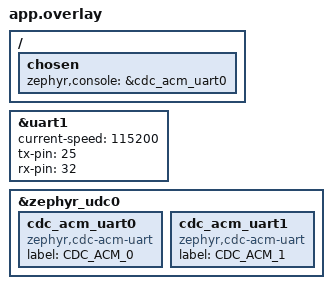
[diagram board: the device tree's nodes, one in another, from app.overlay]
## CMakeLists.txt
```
#
# Copyright (c) Ericsson AB 2020, all rights reserved
#

cmake_minimum_required(VERSION 3.8.2)

set(APP_VERSION "0.10")

# Include Ardesco SDK 
set(AR $ENV{ARDESCO_ROOT})
if(DEFINED AR)
   include($ENV{ARDESCO_ROOT}/ardesco.cmake)
else()
   # Assume we are building from the apps folder in Ardesco tree
   include(${CMAKE_CURRENT_SOURCE_DIR}/../../ardesco.cmake)
endif()

project(IPC52_Simple)

target_sources(app PRIVATE src/main.c)

# Add lib for 91-52 communication 
add_subdirectory(${ARDESCO_LIB_DIR}/ipclib ${CMAKE_BINARY_DIR}/lib/ipclib)

# Add lib for serial on 52840
add_subdirectory(${ARDESCO_LIB_DIR}/serial_52lib ${CMAKE_BINARY_DIR}/lib/serial_52lib)

# Add lib for usb support on 52840
add_subdirectory(${ARDESCO_LIB_DIR}/usb_uart_52lib ${CMAKE_BINARY_DIR}/lib/usb_uart_52lib)
```

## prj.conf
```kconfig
#
# Copyright (c) Ericsson AB 2020, all rights reserved
#

#General
CONFIG_REBOOT=y
CONFIG_HEAP_MEM_POOL_SIZE=16384
CONFIG_GPIO=y
CONFIG_POLL=y
CONFIG_BOOTLOADER_MCUBOOT=y

 # USB
CONFIG_USB_DEVICE_STACK=y
CONFIG_USB_DEVICE_MANUFACTURER="Ericcson AB"
CONFIG_USB_DEVICE_PRODUCT="Ardesco UART"
CONFIG_USB_DEVICE_VID=0x1915
CONFIG_USB_DEVICE_PID=0x520F
CONFIG_USB_DEVICE_SN="ARDESCO 12PLACEHLDRS"
CONFIG_USB_COMPOSITE_DEVICE=y
CONFIG_USB_CDC_ACM_RINGBUF_SIZE=4096

# Set console to USB output
CONFIG_CONSOLE=y
CONFIG_UART_CONSOLE=y

 # UART
CONFIG_SERIAL=y
CONFIG_UART_INTERRUPT_DRIVEN=y
CONFIG_UART_LINE_CTRL=y

# Need power management
CONFIG_DEVICE_POWER_MANAGEMENT=y
```

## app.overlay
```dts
/*
 * Copyright (c) 2021 Nordic Semiconductor ASA
 *
 * SPDX-License-Identifier: Apache-2.0
 */

/ {
	chosen {
		zephyr,console = &cdc_acm_uart0;
	};
};
/* This uses MCU 4 & 5 */
&uart1 {
	current-speed = <115200>;
	status = "okay";
	tx-pin = <25>;
	rx-pin = <32>;
};

&zephyr_udc0 {
	cdc_acm_uart0: cdc_acm_uart0 {
		compatible = "zephyr,cdc-acm-uart";
		label = "CDC_ACM_0";
	};

	cdc_acm_uart1 {
		compatible = "zephyr,cdc-acm-uart";
		label = "CDC_ACM_1";
	};

};
```

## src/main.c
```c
/*
 * Copyright (c) Ericsson AB 2020, all rights reserved
 */

#include <ardesco.h>

#include <ipc_communication.h>
#include <usb_uart.h>

//========================================================
// Program Entry Point
//========================================================
void main(void)
{
	char buf[64];
    printk ("52ipc_simple started\r\n");

	// Init the comms with the 9160
	ipc_init();

	// Init the USB UART relay code.
	usb_uart_init();

	// Loop.
	while (1) 
	{
		printk ("ping52\n");
		k_sleep(K_SECONDS(5));
		//ipc_dbg_out("52Ping via 91");
		ipc_get_coproc_ver(buf, _COUNTOF(buf));
		printk ("9160 firmware version: %s\n", buf);
	}
}
```
